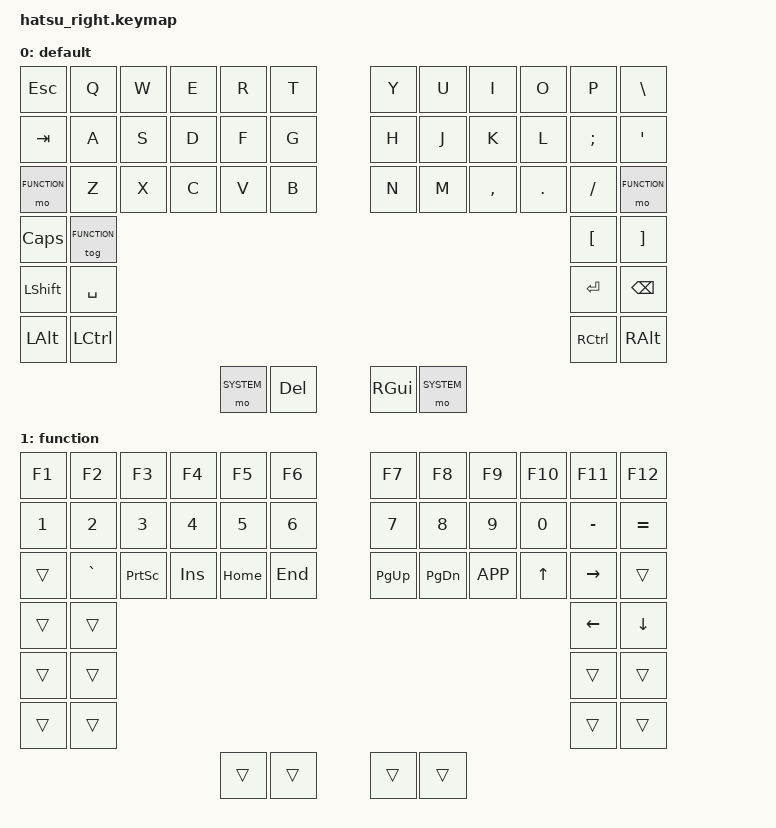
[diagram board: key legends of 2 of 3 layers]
#include <behaviors.dtsi>
#include <dt-bindings/zmk/keys.h>
#include <dt-bindings/zmk/outputs.h>
#include <dt-bindings/zmk/bt.h>
#include <dt-bindings/zmk/backlight.h>

#define DEFAULT 0
#define FUNCTION 1
#define SYSTEM 2

/ {
    behaviors {
        bat: behavior_battery_indicator {
            compatible = "zmk,behavior-battery-indicator";
            display-name = "Battery Indicator";
            #binding-cells = <0>;
        };

        bootl: behavior_hatsu_bootloader {
            compatible = "hatsu,behavior-bootloader";
            display-name = "Bootloader";
            #binding-cells = <0>;
        };
    };

    keymap {
        compatible = "zmk,keymap";
        layer_1 {
            label = "default";
            bindings = <
            &kp ESC &kp Q &kp W &kp E &kp R &kp T           &kp Y &kp U &kp I &kp O &kp P &kp BACKSLASH
            &kp TAB &kp A &kp S &kp D &kp F &kp G           &kp H &kp J &kp K &kp L &kp SEMICOLON &kp APOSTROPHE
            &mo FUNCTION &kp Z &kp X &kp C &kp V &kp B      &kp N &kp M &kp COMMA &kp PERIOD &kp SLASH &mo FUNCTION
                        &kp CAPS &tog FUNCTION                              &kp LBKT &kp RBKT
                        &kp LSHIFT &kp SPACE                                &kp ENTER &kp BACKSPACE
                        &kp LALT &kp LCTRL                                  &kp RCTRL &kp RALT 
                        &mo SYSTEM &kp DEL                                  &kp RGUI &mo SYSTEM
            >;
        };

        layer_2 {
            label = "function";
            bindings = <
            &kp F1 &kp F2 &kp F3 &kp F4 &kp F5 &kp F6                &kp F7 &kp F8 &kp F9 &kp F10 &kp F11 &kp F12
            &kp N1 &kp N2 &kp N3 &kp N4 &kp N5 &kp N6                &kp N7 &kp N8 &kp N9 &kp N0 &kp MINUS &kp EQUAL 
            &trans &kp GRAVE &kp PSCRN &kp INS &kp HOME &kp END      &kp PG_UP &kp PG_DN &kp K_APP &kp UP &kp RIGHT &trans
                        &trans &trans                                             &kp LEFT &kp DOWN 
                        &trans &trans                                             &trans &trans
                        &trans &trans                                             &trans &trans
                        &trans &trans                                             &trans &trans
            >;
        };
        layer_3 {
            label = "system";
            bindings = <
            &bl BL_TOG &bat &sys_reset &bootl &bt BT_CLR &trans                &trans &bt BT_CLR &bootl &sys_reset &bat &bl BL_TOG
            &bt BT_NXT &trans &trans &trans &trans &trans                &trans &trans &trans &trans &trans &trans
            &bt BT_PRV &trans &trans &trans &trans &trans                &trans &trans &trans &trans &trans
                   &trans &trans                                                   &trans &trans
                   &trans &trans                                                   &trans &trans
                   &trans &trans                                                   &trans &trans
            >;
        };
    };
};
